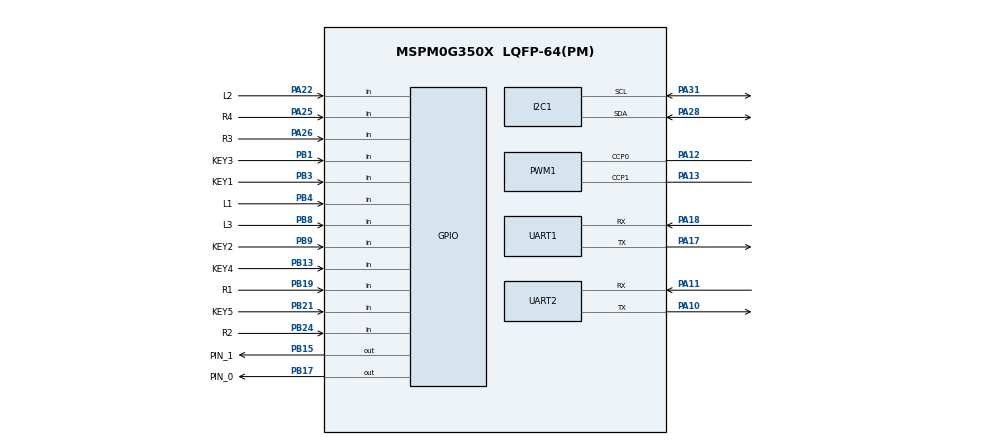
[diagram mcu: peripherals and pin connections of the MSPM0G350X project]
/**
 * @cliArgs --device "MSPM0G350X" --package "LQFP-64(PM)" --part "Default" --product "mspm0_sdk@2.01.00.03"
 * @versions {"tool":"1.20.0+3587"}
 */

/**
 * Import the modules used in this configuration.
 */
const GPIO   = scripting.addModule("/ti/driverlib/GPIO", {}, false);
const GPIO1  = GPIO.addInstance();
const GPIO2  = GPIO.addInstance();
const GPIO3  = GPIO.addInstance();
const GPIO4  = GPIO.addInstance();
const GPIO5  = GPIO.addInstance();
const GPIO6  = GPIO.addInstance();
const GPIO7  = GPIO.addInstance();
const I2C    = scripting.addModule("/ti/driverlib/I2C", {}, false);
const I2C1   = I2C.addInstance();
const PWM    = scripting.addModule("/ti/driverlib/PWM", {}, false);
const PWM1   = PWM.addInstance();
const SYSCTL = scripting.addModule("/ti/driverlib/SYSCTL");
const TIMER  = scripting.addModule("/ti/driverlib/TIMER", {}, false);
const TIMER1 = TIMER.addInstance();
const TIMER2 = TIMER.addInstance();
const UART   = scripting.addModule("/ti/driverlib/UART", {}, false);
const UART1  = UART.addInstance();
const UART2  = UART.addInstance();

/**
 * Write custom configuration values to the imported modules.
 */
GPIO1.$name                          = "LEDS";
GPIO1.associatedPins.create(3);
GPIO1.associatedPins[0].$name        = "LED2_BLUE";
GPIO1.associatedPins[0].assignedPort = "PORTB";
GPIO1.associatedPins[0].assignedPin  = "22";
GPIO1.associatedPins[1].$name        = "LED2_RED";
GPIO1.associatedPins[1].assignedPort = "PORTB";
GPIO1.associatedPins[1].assignedPin  = "26";
GPIO1.associatedPins[2].$name        = "LED2_GREEN";
GPIO1.associatedPins[2].assignedPort = "PORTB";
GPIO1.associatedPins[2].assignedPin  = "27";

const Board = scripting.addModule("/ti/driverlib/Board", {}, false);

GPIO2.$name                          = "motorin";
GPIO2.associatedPins.create(5);
GPIO2.associatedPins[0].$name        = "AIN1";
GPIO2.associatedPins[0].assignedPort = "PORTA";
GPIO2.associatedPins[0].assignedPin  = "8";
GPIO2.associatedPins[1].$name        = "AIN2";
GPIO2.associatedPins[1].assignedPort = "PORTA";
GPIO2.associatedPins[1].assignedPin  = "27";
GPIO2.associatedPins[2].$name        = "BIN1";
GPIO2.associatedPins[2].assignedPort = "PORTB";
GPIO2.associatedPins[2].assignedPin  = "0";
GPIO2.associatedPins[3].$name        = "BIN2";
GPIO2.associatedPins[3].assignedPort = "PORTB";
GPIO2.associatedPins[3].assignedPin  = "6";
GPIO2.associatedPins[4].$name        = "STBY";
GPIO2.associatedPins[4].assignedPort = "PORTB";
GPIO2.associatedPins[4].assignedPin  = "18";

GPIO3.$name                               = "encoder";
GPIO3.associatedPins.create(4);
GPIO3.associatedPins[0].direction         = "INPUT";
GPIO3.associatedPins[0].assignedPort      = "PORTB";
GPIO3.associatedPins[0].assignedPin       = "16";
GPIO3.associatedPins[0].internalResistor  = "PULL_DOWN";
GPIO3.associatedPins[0].polarity          = "RISE";
GPIO3.associatedPins[0].$name             = "AE1";
GPIO3.associatedPins[0].interruptEn       = true;
GPIO3.associatedPins[0].interruptPriority = "0";
GPIO3.associatedPins[1].direction         = "INPUT";
GPIO3.associatedPins[1].assignedPort      = "PORTB";
GPIO3.associatedPins[1].assignedPin       = "20";
GPIO3.associatedPins[1].$name             = "AE2";
GPIO3.associatedPins[2].direction         = "INPUT";
GPIO3.associatedPins[2].assignedPort      = "PORTB";
GPIO3.associatedPins[2].assignedPin       = "2";
GPIO3.associatedPins[2].internalResistor  = "PULL_DOWN";
GPIO3.associatedPins[2].polarity          = "RISE";
GPIO3.associatedPins[2].$name             = "BE1";
GPIO3.associatedPins[3].direction         = "INPUT";
GPIO3.associatedPins[3].assignedPort      = "PORTB";
GPIO3.associatedPins[3].assignedPin       = "12";
GPIO3.associatedPins[3].$name             = "BE2";

GPIO4.$name                          = "huidu8";
GPIO4.associatedPins.create(8);
GPIO4.associatedPins[0].assignedPort = "PORTB";
GPIO4.associatedPins[0].assignedPin  = "7";
GPIO4.associatedPins[0].direction    = "INPUT";
GPIO4.associatedPins[0].$name        = "L4";
GPIO4.associatedPins[1].direction    = "INPUT";
GPIO4.associatedPins[1].$name        = "L3";
GPIO4.associatedPins[1].pin.$assign  = "PB8";
GPIO4.associatedPins[2].assignedPort = "PORTA";
GPIO4.associatedPins[2].assignedPin  = "22";
GPIO4.associatedPins[2].direction    = "INPUT";
GPIO4.associatedPins[2].$name        = "L2";
GPIO4.associatedPins[2].pin.$assign  = "PA22";
GPIO4.associatedPins[3].assignedPort = "PORTB";
GPIO4.associatedPins[3].direction    = "INPUT";
GPIO4.associatedPins[3].assignedPin  = "4";
GPIO4.associatedPins[3].$name        = "L1";
GPIO4.associatedPins[3].pin.$assign  = "PB4";
GPIO4.associatedPins[4].assignedPort = "PORTB";
GPIO4.associatedPins[4].assignedPin  = "19";
GPIO4.associatedPins[4].direction    = "INPUT";
GPIO4.associatedPins[4].$name        = "R1";
GPIO4.associatedPins[4].pin.$assign  = "PB19";
GPIO4.associatedPins[5].$name        = "R2";
GPIO4.associatedPins[5].direction    = "INPUT";
GPIO4.associatedPins[5].pin.$assign  = "PB24";
GPIO4.associatedPins[6].$name        = "R3";
GPIO4.associatedPins[6].direction    = "INPUT";
GPIO4.associatedPins[6].pin.$assign  = "PA26";
GPIO4.associatedPins[7].$name        = "R4";
GPIO4.associatedPins[7].direction    = "INPUT";
GPIO4.associatedPins[7].pin.$assign  = "PA25";

GPIO5.$name                         = "Buzzer";
GPIO5.associatedPins[0].$name       = "PIN_0";
GPIO5.associatedPins[0].pin.$assign = "PB17";

GPIO6.$name                              = "KEYS";
GPIO6.associatedPins.create(5);
GPIO6.associatedPins[0].$name            = "KEY1";
GPIO6.associatedPins[0].direction        = "INPUT";
GPIO6.associatedPins[0].internalResistor = "PULL_UP";
GPIO6.associatedPins[0].assignedPort     = "PORTB";
GPIO6.associatedPins[0].pin.$assign      = "PB3";
GPIO6.associatedPins[1].$name            = "KEY2";
GPIO6.associatedPins[1].direction        = "INPUT";
GPIO6.associatedPins[1].internalResistor = "PULL_UP";
GPIO6.associatedPins[1].pin.$assign      = "PB9";
GPIO6.associatedPins[2].$name            = "KEY3";
GPIO6.associatedPins[2].direction        = "INPUT";
GPIO6.associatedPins[2].internalResistor = "PULL_UP";
GPIO6.associatedPins[2].pin.$assign      = "PB1";
GPIO6.associatedPins[3].$name            = "KEY4";
GPIO6.associatedPins[3].direction        = "INPUT";
GPIO6.associatedPins[3].internalResistor = "PULL_UP";
GPIO6.associatedPins[3].pin.$assign      = "PB13";
GPIO6.associatedPins[4].$name            = "KEY5";
GPIO6.associatedPins[4].direction        = "INPUT";
GPIO6.associatedPins[4].internalResistor = "PULL_UP";
GPIO6.associatedPins[4].pin.$assign      = "PB21";

GPIO7.$name                         = "LED_zzk";
GPIO7.associatedPins[0].$name       = "PIN_1";
GPIO7.associatedPins[0].pin.$assign = "PB15";

I2C1.$name                             = "OLED";
I2C1.basicEnableController             = true;
I2C1.basicControllerBusSpeed           = 400000;
I2C1.peripheral.$assign                = "I2C0";
I2C1.peripheral.sdaPin.$assign         = "PA28";
I2C1.peripheral.sclPin.$assign         = "PA31";
I2C1.sdaPinConfig.$name                = "ti_driverlib_gpio_GPIOPinGeneric0";
I2C1.sdaPinConfig.hideOutputInversion  = scripting.forceWrite(false);
I2C1.sdaPinConfig.onlyInternalResistor = scripting.forceWrite(false);
I2C1.sdaPinConfig.passedPeripheralType = scripting.forceWrite("Digital");
I2C1.sclPinConfig.$name                = "ti_driverlib_gpio_GPIOPinGeneric1";
I2C1.sclPinConfig.hideOutputInversion  = scripting.forceWrite(false);
I2C1.sclPinConfig.onlyInternalResistor = scripting.forceWrite(false);
I2C1.sclPinConfig.passedPeripheralType = scripting.forceWrite("Digital");

PWM1.$name                              = "motorAB";
PWM1.timerCount                         = 32000;
PWM1.pwmMode                            = "EDGE_ALIGN_UP";
PWM1.peripheral.$assign                 = "TIMG0";
PWM1.peripheral.ccp0Pin.$assign         = "PA12";
PWM1.peripheral.ccp1Pin.$assign         = "PA13";
PWM1.PWM_CHANNEL_0.$name                = "ti_driverlib_pwm_PWMTimerCC0";
PWM1.PWM_CHANNEL_1.$name                = "ti_driverlib_pwm_PWMTimerCC1";
PWM1.ccp0PinConfig.direction            = scripting.forceWrite("OUTPUT");
PWM1.ccp0PinConfig.hideOutputInversion  = scripting.forceWrite(false);
PWM1.ccp0PinConfig.onlyInternalResistor = scripting.forceWrite(false);
PWM1.ccp0PinConfig.passedPeripheralType = scripting.forceWrite("Digital");
PWM1.ccp0PinConfig.$name                = "ti_driverlib_gpio_GPIOPinGeneric6";
PWM1.ccp1PinConfig.direction            = scripting.forceWrite("OUTPUT");
PWM1.ccp1PinConfig.hideOutputInversion  = scripting.forceWrite(false);
PWM1.ccp1PinConfig.onlyInternalResistor = scripting.forceWrite(false);
PWM1.ccp1PinConfig.passedPeripheralType = scripting.forceWrite("Digital");
PWM1.ccp1PinConfig.$name                = "ti_driverlib_gpio_GPIOPinGeneric7";

SYSCTL.forceDefaultClkConfig = true;

TIMER1.$name              = "TIM_EncoderA";
TIMER1.timerMode          = "PERIODIC";
TIMER1.interrupts         = ["ZERO"];
TIMER1.timerPeriod        = "100ms";
TIMER1.timerClkPrescale   = 256;
TIMER1.peripheral.$assign = "TIMA1";

TIMER2.$name              = "IMU_RECEIVE_DATA";
TIMER2.timerClkPrescale   = 128;
TIMER2.timerMode          = "PERIODIC";
TIMER2.interrupts         = ["ZERO"];
TIMER2.interruptPriority  = "0";
TIMER2.timerPeriod        = "100ms";
TIMER2.peripheral.$assign = "TIMA0";

UART1.$name                    = "UART_0";
UART1.targetBaudRate           = 115200;
UART1.enabledInterrupts        = ["RX"];
UART1.peripheral.$assign       = "UART1";
UART1.peripheral.rxPin.$assign = "PA18";
UART1.peripheral.txPin.$assign = "PA17";
UART1.txPinConfig.$name        = "ti_driverlib_gpio_GPIOPinGeneric2";
UART1.rxPinConfig.$name        = "ti_driverlib_gpio_GPIOPinGeneric3";

UART2.$name                            = "IMU";
UART2.targetBaudRate                   = 115200;
UART2.interruptPriority                = "0";
UART2.enabledInterrupts                = ["OVERRUN_ERROR","RX"];
UART2.peripheral.$assign               = "UART0";
UART2.peripheral.rxPin.$assign         = "PA11";
UART2.peripheral.txPin.$assign         = "PA10";
UART2.txPinConfig.direction            = scripting.forceWrite("OUTPUT");
UART2.txPinConfig.hideOutputInversion  = scripting.forceWrite(false);
UART2.txPinConfig.onlyInternalResistor = scripting.forceWrite(false);
UART2.txPinConfig.passedPeripheralType = scripting.forceWrite("Digital");
UART2.txPinConfig.$name                = "ti_driverlib_gpio_GPIOPinGeneric4";
UART2.rxPinConfig.hideOutputInversion  = scripting.forceWrite(false);
UART2.rxPinConfig.onlyInternalResistor = scripting.forceWrite(false);
UART2.rxPinConfig.passedPeripheralType = scripting.forceWrite("Digital");
UART2.rxPinConfig.$name                = "ti_driverlib_gpio_GPIOPinGeneric5";

/**
 * Pinmux solution for unlocked pins/peripherals. This ensures that minor changes to the automatic solver in a future
 * version of the tool will not impact the pinmux you originally saw.  These lines can be completely deleted in order to
 * re-solve from scratch.
 */
GPIO1.associatedPins[0].pin.$suggestSolution = "PB22";
GPIO1.associatedPins[1].pin.$suggestSolution = "PB26";
GPIO1.associatedPins[2].pin.$suggestSolution = "PB27";
Board.peripheral.$suggestSolution            = "DEBUGSS";
Board.peripheral.swclkPin.$suggestSolution   = "PA20";
Board.peripheral.swdioPin.$suggestSolution   = "PA19";
GPIO2.associatedPins[0].pin.$suggestSolution = "PA8";
GPIO2.associatedPins[1].pin.$suggestSolution = "PA27";
GPIO2.associatedPins[2].pin.$suggestSolution = "PB0";
GPIO2.associatedPins[3].pin.$suggestSolution = "PB6";
GPIO2.associatedPins[4].pin.$suggestSolution = "PB18";
GPIO3.associatedPins[0].pin.$suggestSolution = "PB16";
GPIO3.associatedPins[1].pin.$suggestSolution = "PB20";
GPIO3.associatedPins[2].pin.$suggestSolution = "PB2";
GPIO3.associatedPins[3].pin.$suggestSolution = "PB12";
GPIO4.associatedPins[0].pin.$suggestSolution = "PB7";
SYSCTL.peripheral.$suggestSolution           = "SYSCTL";
